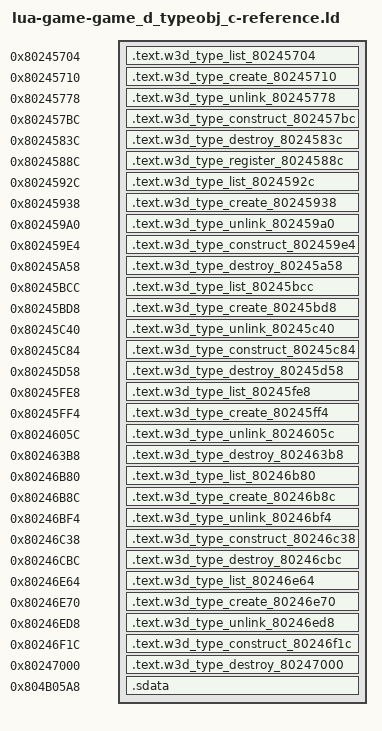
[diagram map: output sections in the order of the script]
/* Generated reference-only placements. All bodies are source-built. */
OUTPUT_FORMAT("elf32-powerpc")
OUTPUT_ARCH(powerpc)
ENTRY(w3d_type_list_80245704)
_SDA_BASE_ = 0x804b2540;
_SDA2_BASE_ = 0x804c2540;
w3d_f32_803c22cc = 0x803c22cc;
w3d_f32_803c22d0 = 0x803c22d0;
w3d_f32_803c22d4 = 0x803c22d4;
w3d_f32_803c23d0 = 0x803c23d0;
w3d_f32_803c2484 = 0x803c2484;
w3d_f32_803c2488 = 0x803c2488;
w3d_f32_803c33b0 = 0x803c33b0;
w3d_f32_803c356c = 0x803c356c;
w3d_object_alloc_801ea70c = 0x801ea70c;
w3d_object_base_construct_801ea0ec = 0x801ea0ec;
w3d_object_base_destroy_801ea138 = 0x801ea138;
w3d_object_free_801ea740 = 0x801ea740;
w3d_owner_list_remove = 0x8020fd2c;
w3d_script_add_color_801f15e0 = 0x801f15e0;
w3d_script_add_prop_801ec52c = 0x801ec52c;
w3d_script_add_prop_801ece2c = 0x801ece2c;
w3d_script_finish_type_801e8d9c = 0x801e8d9c;
w3d_script_prop_803c22d8 = 0x803c22d8;
w3d_script_prop_803c2308 = 0x803c2308;
w3d_script_prop_803c2338 = 0x803c2338;
w3d_script_prop_803c2368 = 0x803c2368;
w3d_script_prop_803c2394 = 0x803c2394;
w3d_state_register = 0x8020fd04;
w3d_string_base_finish = 0x8020c5c4;
w3d_string_release = 0x80341588;
w3d_type_construct_802460a0 = 0x802460a0;
w3d_type_list_803679c8 = 0x803679c8;
w3d_type_list_80367a18 = 0x80367a18;
w3d_type_list_80367a68 = 0x80367a68;
w3d_type_list_80367ab8 = 0x80367ab8;
w3d_type_list_80367b08 = 0x80367b08;
w3d_type_list_80367b58 = 0x80367b58;
w3d_vtable_8041b338 = 0x8041b338;
w3d_vtable_8041b360 = 0x8041b360;
w3d_vtable_8041b388 = 0x8041b388;
w3d_vtable_8041b3b0 = 0x8041b3b0;
w3d_vtable_8041b3d8 = 0x8041b3d8;
w3d_vtable_8041b400 = 0x8041b400;
SECTIONS {
  .text.w3d_type_list_80245704 0x80245704 : { *(.text.w3d_type_list_80245704) }
  .text.w3d_type_create_80245710 0x80245710 : { *(.text.w3d_type_create_80245710) }
  .text.w3d_type_unlink_80245778 0x80245778 : { *(.text.w3d_type_unlink_80245778) }
  .text.w3d_type_construct_802457bc 0x802457bc : { *(.text.w3d_type_construct_802457bc) }
  .text.w3d_type_destroy_8024583c 0x8024583c : { *(.text.w3d_type_destroy_8024583c) }
  .text.w3d_type_register_8024588c 0x8024588c : { *(.text.w3d_type_register_8024588c) }
  .text.w3d_type_list_8024592c 0x8024592c : { *(.text.w3d_type_list_8024592c) }
  .text.w3d_type_create_80245938 0x80245938 : { *(.text.w3d_type_create_80245938) }
  .text.w3d_type_unlink_802459a0 0x802459a0 : { *(.text.w3d_type_unlink_802459a0) }
  .text.w3d_type_construct_802459e4 0x802459e4 : { *(.text.w3d_type_construct_802459e4) }
  .text.w3d_type_destroy_80245a58 0x80245a58 : { *(.text.w3d_type_destroy_80245a58) }
  .text.w3d_type_list_80245bcc 0x80245bcc : { *(.text.w3d_type_list_80245bcc) }
  .text.w3d_type_create_80245bd8 0x80245bd8 : { *(.text.w3d_type_create_80245bd8) }
  .text.w3d_type_unlink_80245c40 0x80245c40 : { *(.text.w3d_type_unlink_80245c40) }
  .text.w3d_type_construct_80245c84 0x80245c84 : { *(.text.w3d_type_construct_80245c84) }
  .text.w3d_type_destroy_80245d58 0x80245d58 : { *(.text.w3d_type_destroy_80245d58) }
  .text.w3d_type_list_80245fe8 0x80245fe8 : { *(.text.w3d_type_list_80245fe8) }
  .text.w3d_type_create_80245ff4 0x80245ff4 : { *(.text.w3d_type_create_80245ff4) }
  .text.w3d_type_unlink_8024605c 0x8024605c : { *(.text.w3d_type_unlink_8024605c) }
  .text.w3d_type_destroy_802463b8 0x802463b8 : { *(.text.w3d_type_destroy_802463b8) }
  .text.w3d_type_list_80246b80 0x80246b80 : { *(.text.w3d_type_list_80246b80) }
  .text.w3d_type_create_80246b8c 0x80246b8c : { *(.text.w3d_type_create_80246b8c) }
  .text.w3d_type_unlink_80246bf4 0x80246bf4 : { *(.text.w3d_type_unlink_80246bf4) }
  .text.w3d_type_construct_80246c38 0x80246c38 : { *(.text.w3d_type_construct_80246c38) }
  .text.w3d_type_destroy_80246cbc 0x80246cbc : { *(.text.w3d_type_destroy_80246cbc) }
  .text.w3d_type_list_80246e64 0x80246e64 : { *(.text.w3d_type_list_80246e64) }
  .text.w3d_type_create_80246e70 0x80246e70 : { *(.text.w3d_type_create_80246e70) }
  .text.w3d_type_unlink_80246ed8 0x80246ed8 : { *(.text.w3d_type_unlink_80246ed8) }
  .text.w3d_type_construct_80246f1c 0x80246f1c : { *(.text.w3d_type_construct_80246f1c) }
  .text.w3d_type_destroy_80247000 0x80247000 : { *(.text.w3d_type_destroy_80247000) }
  .sdata 0x804b05a8 (NOLOAD) : {
    . = 0x0; w3d_shared_iface_804b05a8 = .;
    . = 0x4; w3d_shared_iface_804b05ac = .;
    . += 1; }
  /DISCARD/ : { *(.text*) *(.rodata*) *(.data*) *(.bss*) *(.sdata*) *(.sbss*) *(.comment) }
}
